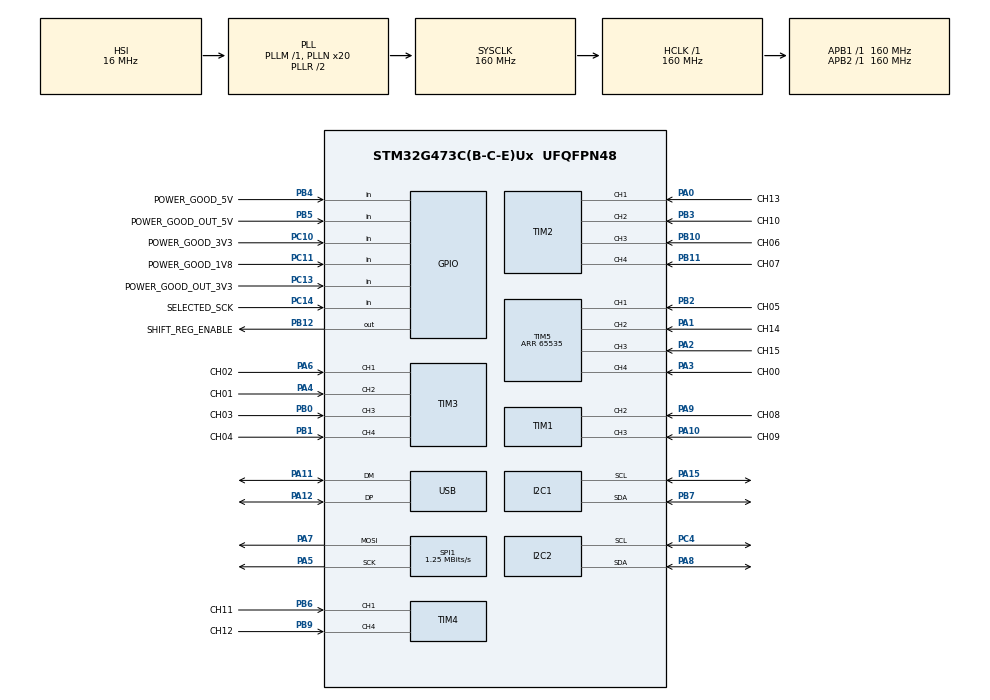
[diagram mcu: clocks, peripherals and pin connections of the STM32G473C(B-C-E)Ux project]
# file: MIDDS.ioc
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I2C1.Timing=0x30D29DE4
I2C2.Timing=0x30D29DE4
Mcu.Family=STM32G4
Mcu.Name=STM32G473C(B-C-E)Ux
Mcu.Package=UFQFPN48
NVIC.PriorityGroup=NVIC_PRIORITYGROUP_4
NVIC.TIM1_CC_IRQn=true\:0\:0\:false\:false\:true\:true\:true\:true
NVIC.TIM1_UP_TIM16_IRQn=true\:0\:0\:false\:false\:true\:true\:true\:true
NVIC.TIM2_IRQn=true\:0\:0\:false\:false\:true\:true\:true\:true
NVIC.TIM3_IRQn=true\:0\:0\:false\:false\:true\:true\:true\:true
NVIC.TIM4_IRQn=true\:0\:0\:false\:false\:true\:true\:true\:true
NVIC.TIM5_IRQn=true\:0\:0\:false\:false\:true\:true\:true\:true
NVIC.USB_LP_IRQn=true\:0\:0\:false\:false\:true\:false\:true\:true
PA0.GPIO_Label=CH13
PA0.GPIO_PuPd=GPIO_PULLDOWN
PA0.Signal=S_TIM2_CH1
PA1.GPIO_Label=CH14
PA1.GPIO_PuPd=GPIO_PULLDOWN
PA1.Signal=S_TIM5_CH2
PA10.GPIO_Label=CH09
PA10.GPIO_PuPd=GPIO_PULLDOWN
PA10.Signal=S_TIM1_CH3
PA11.Mode=Device
PA11.Signal=USB_DM
PA12.Mode=Device
PA12.Signal=USB_DP
PA13.Mode=Serial_Wire
PA13.Signal=SYS_JTMS-SWDIO
PA14.Mode=Serial_Wire
PA14.Signal=SYS_JTCK-SWCLK
PA15.Mode=I2C
PA15.Signal=I2C1_SCL
PA2.GPIO_Label=CH15
PA2.GPIO_PuPd=GPIO_PULLDOWN
PA2.Signal=S_TIM5_CH3
PA3.GPIO_Label=CH00
PA3.GPIO_PuPd=GPIO_PULLDOWN
PA3.Signal=S_TIM5_CH4
PA4.GPIO_Label=CH01
PA4.GPIO_PuPd=GPIO_PULLDOWN
PA4.Signal=S_TIM3_CH2
PA5.Mode=TX_Only_Simplex_Unidirect_Master
PA5.Signal=SPI1_SCK
PA6.GPIO_Label=CH02
PA6.GPIO_PuPd=GPIO_PULLDOWN
PA6.Signal=S_TIM3_CH1
PA7.Mode=TX_Only_Simplex_Unidirect_Master
PA7.Signal=SPI1_MOSI
PA8.Mode=I2C
PA8.Signal=I2C2_SDA
PA9.GPIO_Label=CH08
PA9.GPIO_PuPd=GPIO_PULLDOWN
PA9.Signal=S_TIM1_CH2
PB0.GPIO_Label=CH03
PB0.GPIO_PuPd=GPIO_PULLDOWN
PB0.Signal=S_TIM3_CH3
PB1.GPIO_Label=CH04
PB1.GPIO_PuPd=GPIO_PULLDOWN
PB1.Signal=S_TIM3_CH4
PB10.GPIO_Label=CH06
PB10.GPIO_PuPd=GPIO_PULLDOWN
PB10.Signal=S_TIM2_CH3
PB11.GPIO_Label=CH07
PB11.GPIO_PuPd=GPIO_PULLDOWN
PB11.Signal=S_TIM2_CH4
PB12.GPIO_Label=SHIFT_REG_ENABLE
PB12.Signal=GPIO_Output
PB2.GPIO_Label=CH05
PB2.GPIO_PuPd=GPIO_PULLDOWN
PB2.Signal=S_TIM5_CH1
PB3.GPIO_Label=CH10
PB3.GPIO_PuPd=GPIO_PULLDOWN
PB3.Signal=S_TIM2_CH2
PB4.GPIO_Label=POWER_GOOD_5V
PB4.Signal=GPIO_Input
PB5.GPIO_Label=POWER_GOOD_OUT_5V
PB5.Signal=GPIO_Input
PB6.GPIO_Label=CH11
PB6.GPIO_PuPd=GPIO_PULLDOWN
PB6.Signal=S_TIM4_CH1
PB7.Mode=I2C
PB7.Signal=I2C1_SDA
PB9.GPIO_Label=CH12
PB9.GPIO_PuPd=GPIO_PULLDOWN
PB9.Signal=S_TIM4_CH4
PC10.GPIO_Label=POWER_GOOD_3V3
PC10.Signal=GPIO_Input
PC11.GPIO_Label=POWER_GOOD_1V8
PC11.Signal=GPIO_Input
PC13.GPIO_Label=POWER_GOOD_OUT_3V3
PC13.Signal=GPIO_Input
PC14-OSC32_IN.GPIO_Label=SELECTED_SCK
PC14-OSC32_IN.Signal=GPIO_Input
PC4.Mode=I2C
PC4.Signal=I2C2_SCL
PF0-OSC_IN.Mode=HSE-External-Clock-Source
PF0-OSC_IN.Signal=RCC_OSC_IN
ProjectManager.HeapSize=0x200
ProjectManager.StackSize=0x400
ProjectManager.TargetToolchain=STM32CubeIDE
RCC.ADC12Freq_Value=160000000
RCC.ADC345Freq_Value=160000000
RCC.AHBFreq_Value=160000000
RCC.APB1Freq_Value=160000000
RCC.APB1TimFreq_Value=160000000
RCC.APB2Freq_Value=160000000
RCC.APB2TimFreq_Value=160000000
RCC.CK48CLockSelection=RCC_USBCLKSOURCE_HSI48
RCC.CortexFreq_Value=160000000
RCC.EXTERNAL_CLOCK_VALUE=12288000
RCC.HCLKFreq_Value=160000000
RCC.HSE_VALUE=10000000
RCC.HSI48_VALUE=48000000
RCC.HSI_VALUE=16000000
RCC.LSE_VALUE=32768
RCC.PLLN=20
RCC.PLLQ=RCC_PLLQ_DIV4
RCC.SYSCLKFreq_VALUE=160000000
RCC.SYSCLKSource=RCC_SYSCLKSOURCE_PLLCLK
RCC.USBFreq_Value=48000000
RCC.VCOOutputFreq_Value=320000000
SH.S_TIM1_CH2.0=TIM1_CH2,Input_Capture2_from_TI2
SH.S_TIM1_CH3.0=TIM1_CH3,Input_Capture3_from_TI3
SH.S_TIM2_CH1.0=TIM2_CH1,Input_Capture1_from_TI1
SH.S_TIM2_CH2.0=TIM2_CH2,Input_Capture2_from_TI2
SH.S_TIM2_CH3.0=TIM2_CH3,Input_Capture3_from_TI3
SH.S_TIM2_CH4.0=TIM2_CH4,Input_Capture4_from_TI4
SH.S_TIM3_CH1.0=TIM3_CH1,Input_Capture1_from_TI1
SH.S_TIM3_CH2.0=TIM3_CH2,Input_Capture2_from_TI2
SH.S_TIM3_CH3.0=TIM3_CH3,Input_Capture3_from_TI3
SH.S_TIM3_CH4.0=TIM3_CH4,Input_Capture4_from_TI4
SH.S_TIM4_CH1.0=TIM4_CH1,Input_Capture1_from_TI1
SH.S_TIM4_CH4.0=TIM4_CH4,Input_Capture4_from_TI4
SH.S_TIM5_CH1.0=TIM5_CH1,Input_Capture1_from_TI1
SH.S_TIM5_CH2.0=TIM5_CH2,Input_Capture2_from_TI2
SH.S_TIM5_CH3.0=TIM5_CH3,Input_Capture3_from_TI3
SH.S_TIM5_CH4.0=TIM5_CH4,Input_Capture4_from_TI4
SPI1.BaudRatePrescaler=SPI_BAUDRATEPRESCALER_128
SPI1.CalculateBaudRate=1.25 MBits/s
SPI1.DataSize=SPI_DATASIZE_8BIT
SPI1.Direction=SPI_DIRECTION_2LINES
SPI1.Mode=SPI_MODE_MASTER
SPI1.VirtualType=VM_MASTER
TIM1.Channel-Input_Capture1_from_TI1=TIM_CHANNEL_1
TIM1.Channel-Input_Capture2_from_TI2=TIM_CHANNEL_2
TIM1.Channel-Input_Capture3_from_TI3=TIM_CHANNEL_3
TIM1.ICPolarity_CH1=TIM_INPUTCHANNELPOLARITY_BOTHEDGE
TIM1.ICPolarity_CH2=TIM_INPUTCHANNELPOLARITY_BOTHEDGE
TIM1.ICPolarity_CH3=TIM_INPUTCHANNELPOLARITY_BOTHEDGE
TIM1.TIM_MasterOutputTrigger=TIM_TRGO_ENABLE
TIM1.TIM_MasterSlaveMode=TIM_MASTERSLAVEMODE_ENABLE
TIM2.Channel-Input_Capture1_from_TI1=TIM_CHANNEL_1
TIM2.Channel-Input_Capture2_from_TI2=TIM_CHANNEL_2
TIM2.Channel-Input_Capture3_from_TI3=TIM_CHANNEL_3
TIM2.Channel-Input_Capture4_from_TI4=TIM_CHANNEL_4
TIM2.ICPolarity_CH1=TIM_INPUTCHANNELPOLARITY_BOTHEDGE
TIM2.ICPolarity_CH2=TIM_INPUTCHANNELPOLARITY_BOTHEDGE
TIM2.ICPolarity_CH3=TIM_INPUTCHANNELPOLARITY_BOTHEDGE
TIM2.ICPolarity_CH4=TIM_INPUTCHANNELPOLARITY_BOTHEDGE
TIM3.Channel-Input_Capture1_from_TI1=TIM_CHANNEL_1
TIM3.Channel-Input_Capture2_from_TI2=TIM_CHANNEL_2
TIM3.Channel-Input_Capture3_from_TI3=TIM_CHANNEL_3
TIM3.Channel-Input_Capture4_from_TI4=TIM_CHANNEL_4
TIM3.ICPolarity_CH1=TIM_INPUTCHANNELPOLARITY_BOTHEDGE
TIM3.ICPolarity_CH2=TIM_INPUTCHANNELPOLARITY_BOTHEDGE
TIM3.ICPolarity_CH3=TIM_INPUTCHANNELPOLARITY_BOTHEDGE
TIM3.ICPolarity_CH4=TIM_INPUTCHANNELPOLARITY_BOTHEDGE
TIM4.Channel-Input_Capture1_from_TI1=TIM_CHANNEL_1
TIM4.Channel-Input_Capture4_from_TI4=TIM_CHANNEL_4
TIM4.ICPolarity_CH1=TIM_INPUTCHANNELPOLARITY_BOTHEDGE
TIM4.ICPolarity_CH4=TIM_INPUTCHANNELPOLARITY_BOTHEDGE
TIM5.Channel-Input_Capture1_from_TI1=TIM_CHANNEL_1
TIM5.Channel-Input_Capture2_from_TI2=TIM_CHANNEL_2
TIM5.Channel-Input_Capture3_from_TI3=TIM_CHANNEL_3
TIM5.Channel-Input_Capture4_from_TI4=TIM_CHANNEL_4
TIM5.PeriodNoDither=65535
USB_DEVICE.CLASS_NAME_FS=CDC
USB_DEVICE.VirtualMode=Cdc
USB_DEVICE.VirtualModeFS=Cdc_FS
VP_SYS_VS_DBSignals.Mode=DisableDeadBatterySignals
VP_TIM1_VS_ClockSourceINT.Mode=Internal
VP_TIM2_VS_ClockSourceINT.Mode=Internal
VP_TIM2_VS_ClockSourceITR.Mode=TriggerSource_ITR0
VP_TIM2_VS_ControllerModeReset.Mode=Reset Mode
VP_TIM3_VS_ClockSourceINT.Mode=Internal
VP_TIM3_VS_ClockSourceITR.Mode=TriggerSource_ITR0
VP_TIM3_VS_ControllerModeReset.Mode=Reset Mode
VP_TIM4_VS_ClockSourceINT.Mode=Internal
VP_TIM4_VS_ClockSourceITR.Mode=TriggerSource_ITR0
VP_TIM4_VS_ControllerModeReset.Mode=Reset Mode
VP_TIM5_VS_ClockSourceINT.Mode=Internal
VP_TIM5_VS_ClockSourceITR.Mode=TriggerSource_ITR0
VP_TIM5_VS_ControllerModeReset.Mode=Reset Mode
VP_USB_DEVICE_VS_USB_DEVICE_CDC_FS.Mode=CDC_FS
board=custom

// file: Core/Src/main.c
/* USER CODE BEGIN Header */
/**
  ******************************************************************************
  * @file           : main.c
  * @brief          : Main program body
  ******************************************************************************
  * @attention
  *
  * Copyright (c) 2025 STMicroelectronics.
  * All rights reserved.
  *
  * This software is licensed under terms that can be found in the LICENSE file
  * in the root directory of this software component.
  * If no LICENSE file comes with this software, it is provided AS-IS.
  *
  ******************************************************************************
  */
/* USER CODE END Header */
#include "main.h"
#include "usb_device.h"

/* USER CODE BEGIN Includes */
#include "MainMCU.h"
/* USER CODE END Includes */

I2C_HandleTypeDef hi2c1;
I2C_HandleTypeDef hi2c2;

SPI_HandleTypeDef hspi1;

TIM_HandleTypeDef htim1;
TIM_HandleTypeDef htim2;
TIM_HandleTypeDef htim3;
TIM_HandleTypeDef htim4;
TIM_HandleTypeDef htim5;

void SystemClock_Config(void);
static void MX_GPIO_Init(void);
static void MX_TIM1_Init(void);
static void MX_TIM2_Init(void);
static void MX_TIM3_Init(void);
static void MX_TIM4_Init(void);
static void MX_I2C1_Init(void);
static void MX_I2C2_Init(void);
static void MX_SPI1_Init(void);
static void MX_TIM5_Init(void);

int main(void)
{

  /* MCU Configuration--------------------------------------------------------*/

  /* Reset of all peripherals, Initializes the Flash interface and the Systick. */
  HAL_Init();

  /* Configure the system clock */
  SystemClock_Config();

  /* Initialize all configured peripherals */
  MX_GPIO_Init();
  MX_TIM1_Init();
  MX_TIM2_Init();
  MX_TIM3_Init();
  MX_TIM4_Init();
  MX_USB_Device_Init();
  MX_I2C1_Init();
  MX_I2C2_Init();
  MX_SPI1_Init();
  MX_TIM5_Init();
  /* USER CODE BEGIN 2 */
  initMCU(&htim1, &htim2, &htim3, &htim4, &htim5, &hspi1, &hi2c1, &hi2c2);
  /* USER CODE END 2 */

  /* Infinite loop */
  while (1)
  {

    /* USER CODE BEGIN 3 */
    loopMCU();
  }
  /* USER CODE END 3 */
}

void SystemClock_Config(void)
{
  RCC_OscInitTypeDef RCC_OscInitStruct = {0};
  RCC_ClkInitTypeDef RCC_ClkInitStruct = {0};

  /** Configure the main internal regulator output voltage
  */
  HAL_PWREx_ControlVoltageScaling(PWR_REGULATOR_VOLTAGE_SCALE1_BOOST);

  /** Initializes the RCC Oscillators according to the specified parameters
  * in the RCC_OscInitTypeDef structure.
  */
  RCC_OscInitStruct.OscillatorType = RCC_OSCILLATORTYPE_HSI|RCC_OSCILLATORTYPE_HSI48;
  RCC_OscInitStruct.HSIState = RCC_HSI_ON;
  RCC_OscInitStruct.HSICalibrationValue = RCC_HSICALIBRATION_DEFAULT;
  RCC_OscInitStruct.HSI48State = RCC_HSI48_ON;
  RCC_OscInitStruct.PLL.PLLState = RCC_PLL_ON;
  RCC_OscInitStruct.PLL.PLLSource = RCC_PLLSOURCE_HSI;
  RCC_OscInitStruct.PLL.PLLM = RCC_PLLM_DIV1;
  RCC_OscInitStruct.PLL.PLLN = 20;
  RCC_OscInitStruct.PLL.PLLP = RCC_PLLP_DIV2;
  RCC_OscInitStruct.PLL.PLLQ = RCC_PLLQ_DIV4;
  RCC_OscInitStruct.PLL.PLLR = RCC_PLLR_DIV2;
  if (HAL_RCC_OscConfig(&RCC_OscInitStruct) != HAL_OK)
  {
    Error_Handler();
  }

  /** Initializes the CPU, AHB and APB buses clocks
  */
  RCC_ClkInitStruct.ClockType = RCC_CLOCKTYPE_HCLK|RCC_CLOCKTYPE_SYSCLK
                              |RCC_CLOCKTYPE_PCLK1|RCC_CLOCKTYPE_PCLK2;
  RCC_ClkInitStruct.SYSCLKSource = RCC_SYSCLKSOURCE_PLLCLK;
  RCC_ClkInitStruct.AHBCLKDivider = RCC_SYSCLK_DIV1;
  RCC_ClkInitStruct.APB1CLKDivider = RCC_HCLK_DIV1;
  RCC_ClkInitStruct.APB2CLKDivider = RCC_HCLK_DIV1;

  if (HAL_RCC_ClockConfig(&RCC_ClkInitStruct, FLASH_LATENCY_4) != HAL_OK)
  {
    Error_Handler();
  }
}

static void MX_I2C1_Init(void)
{

  hi2c1.Instance = I2C1;
  hi2c1.Init.Timing = 0x30D29DE4;
  hi2c1.Init.OwnAddress1 = 0;
  hi2c1.Init.AddressingMode = I2C_ADDRESSINGMODE_7BIT;
  hi2c1.Init.DualAddressMode = I2C_DUALADDRESS_DISABLE;
  hi2c1.Init.OwnAddress2 = 0;
  hi2c1.Init.OwnAddress2Masks = I2C_OA2_NOMASK;
  hi2c1.Init.GeneralCallMode = I2C_GENERALCALL_DISABLE;
  hi2c1.Init.NoStretchMode = I2C_NOSTRETCH_DISABLE;
  if (HAL_I2C_Init(&hi2c1) != HAL_OK)
  {
    Error_Handler();
  }

  /** Configure Analogue filter
  */
  if (HAL_I2CEx_ConfigAnalogFilter(&hi2c1, I2C_ANALOGFILTER_ENABLE) != HAL_OK)
  {
    Error_Handler();
  }

  /** Configure Digital filter
  */
  if (HAL_I2CEx_ConfigDigitalFilter(&hi2c1, 0) != HAL_OK)
  {
    Error_Handler();
  }

}

static void MX_I2C2_Init(void)
{

  hi2c2.Instance = I2C2;
  hi2c2.Init.Timing = 0x30D29DE4;
  hi2c2.Init.OwnAddress1 = 0;
  hi2c2.Init.AddressingMode = I2C_ADDRESSINGMODE_7BIT;
  hi2c2.Init.DualAddressMode = I2C_DUALADDRESS_DISABLE;
  hi2c2.Init.OwnAddress2 = 0;
  hi2c2.Init.OwnAddress2Masks = I2C_OA2_NOMASK;
  hi2c2.Init.GeneralCallMode = I2C_GENERALCALL_DISABLE;
  hi2c2.Init.NoStretchMode = I2C_NOSTRETCH_DISABLE;
  if (HAL_I2C_Init(&hi2c2) != HAL_OK)
  {
    Error_Handler();
  }

  /** Configure Analogue filter
  */
  if (HAL_I2CEx_ConfigAnalogFilter(&hi2c2, I2C_ANALOGFILTER_ENABLE) != HAL_OK)
  {
    Error_Handler();
  }

  /** Configure Digital filter
  */
  if (HAL_I2CEx_ConfigDigitalFilter(&hi2c2, 0) != HAL_OK)
  {
    Error_Handler();
  }

}

static void MX_SPI1_Init(void)
{

  /* SPI1 parameter configuration*/
  hspi1.Instance = SPI1;
  hspi1.Init.Mode = SPI_MODE_MASTER;
  hspi1.Init.Direction = SPI_DIRECTION_2LINES;
  hspi1.Init.DataSize = SPI_DATASIZE_8BIT;
  hspi1.Init.CLKPolarity = SPI_POLARITY_LOW;
  hspi1.Init.CLKPhase = SPI_PHASE_1EDGE;
  hspi1.Init.NSS = SPI_NSS_SOFT;
  hspi1.Init.BaudRatePrescaler = SPI_BAUDRATEPRESCALER_128;
  hspi1.Init.FirstBit = SPI_FIRSTBIT_MSB;
  hspi1.Init.TIMode = SPI_TIMODE_DISABLE;
  hspi1.Init.CRCCalculation = SPI_CRCCALCULATION_DISABLE;
  hspi1.Init.CRCPolynomial = 7;
  hspi1.Init.CRCLength = SPI_CRC_LENGTH_DATASIZE;
  hspi1.Init.NSSPMode = SPI_NSS_PULSE_ENABLE;
  if (HAL_SPI_Init(&hspi1) != HAL_OK)
  {
    Error_Handler();
  }

}

static void MX_TIM1_Init(void)
{

  TIM_ClockConfigTypeDef sClockSourceConfig = {0};
  TIM_MasterConfigTypeDef sMasterConfig = {0};
  TIM_IC_InitTypeDef sConfigIC = {0};

  htim1.Instance = TIM1;
  htim1.Init.Prescaler = 0;
  htim1.Init.CounterMode = TIM_COUNTERMODE_UP;
  htim1.Init.Period = 65535;
  htim1.Init.ClockDivision = TIM_CLOCKDIVISION_DIV1;
  htim1.Init.RepetitionCounter = 0;
  htim1.Init.AutoReloadPreload = TIM_AUTORELOAD_PRELOAD_DISABLE;
  if (HAL_TIM_Base_Init(&htim1) != HAL_OK)
  {
    Error_Handler();
  }
  sClockSourceConfig.ClockSource = TIM_CLOCKSOURCE_INTERNAL;
  if (HAL_TIM_ConfigClockSource(&htim1, &sClockSourceConfig) != HAL_OK)
  {
    Error_Handler();
  }
  if (HAL_TIM_IC_Init(&htim1) != HAL_OK)
  {
    Error_Handler();
  }
  sMasterConfig.MasterOutputTrigger = TIM_TRGO_ENABLE;
  sMasterConfig.MasterOutputTrigger2 = TIM_TRGO2_RESET;
  sMasterConfig.MasterSlaveMode = TIM_MASTERSLAVEMODE_ENABLE;
  if (HAL_TIMEx_MasterConfigSynchronization(&htim1, &sMasterConfig) != HAL_OK)
  {
    Error_Handler();
  }
  sConfigIC.ICPolarity = TIM_INPUTCHANNELPOLARITY_BOTHEDGE;
  sConfigIC.ICSelection = TIM_ICSELECTION_DIRECTTI;
  sConfigIC.ICPrescaler = TIM_ICPSC_DIV1;
  sConfigIC.ICFilter = 0;
  if (HAL_TIM_IC_ConfigChannel(&htim1, &sConfigIC, TIM_CHANNEL_2) != HAL_OK)
  {
    Error_Handler();
  }
  if (HAL_TIM_IC_ConfigChannel(&htim1, &sConfigIC, TIM_CHANNEL_3) != HAL_OK)
  {
    Error_Handler();
  }

}

static void MX_TIM2_Init(void)
{

  TIM_ClockConfigTypeDef sClockSourceConfig = {0};
  TIM_SlaveConfigTypeDef sSlaveConfig = {0};
  TIM_MasterConfigTypeDef sMasterConfig = {0};
  TIM_IC_InitTypeDef sConfigIC = {0};

  htim2.Instance = TIM2;
  htim2.Init.Prescaler = 0;
  htim2.Init.CounterMode = TIM_COUNTERMODE_UP;
  htim2.Init.Period = 4294967295;
  htim2.Init.ClockDivision = TIM_CLOCKDIVISION_DIV1;
  htim2.Init.AutoReloadPreload = TIM_AUTORELOAD_PRELOAD_DISABLE;
  if (HAL_TIM_Base_Init(&htim2) != HAL_OK)
  {
    Error_Handler();
  }
  sClockSourceConfig.ClockSource = TIM_CLOCKSOURCE_INTERNAL;
  if (HAL_TIM_ConfigClockSource(&htim2, &sClockSourceConfig) != HAL_OK)
  {
    Error_Handler();
  }
  if (HAL_TIM_IC_Init(&htim2) != HAL_OK)
  {
    Error_Handler();
  }
  sSlaveConfig.SlaveMode = TIM_SLAVEMODE_RESET;
  sSlaveConfig.InputTrigger = TIM_TS_ITR0;
  if (HAL_TIM_SlaveConfigSynchro(&htim2, &sSlaveConfig) != HAL_OK)
  {
    Error_Handler();
  }
  sMasterConfig.MasterOutputTrigger = TIM_TRGO_RESET;
  sMasterConfig.MasterSlaveMode = TIM_MASTERSLAVEMODE_DISABLE;
  if (HAL_TIMEx_MasterConfigSynchronization(&htim2, &sMasterConfig) != HAL_OK)
  {
    Error_Handler();
  }
  sConfigIC.ICPolarity = TIM_INPUTCHANNELPOLARITY_BOTHEDGE;
  sConfigIC.ICSelection = TIM_ICSELECTION_DIRECTTI;
  sConfigIC.ICPrescaler = TIM_ICPSC_DIV1;
  sConfigIC.ICFilter = 0;
  if (HAL_TIM_IC_ConfigChannel(&htim2, &sConfigIC, TIM_CHANNEL_1) != HAL_OK)
  {
    Error_Handler();
  }
  if (HAL_TIM_IC_ConfigChannel(&htim2, &sConfigIC, TIM_CHANNEL_2) != HAL_OK)
  {
    Error_Handler();
  }
  if (HAL_TIM_IC_ConfigChannel(&htim2, &sConfigIC, TIM_CHANNEL_3) != HAL_OK)
  {
    Error_Handler();
  }
  if (HAL_TIM_IC_ConfigChannel(&htim2, &sConfigIC, TIM_CHANNEL_4) != HAL_OK)
  {
    Error_Handler();
  }

}

static void MX_TIM3_Init(void)
{

  TIM_ClockConfigTypeDef sClockSourceConfig = {0};
  TIM_SlaveConfigTypeDef sSlaveConfig = {0};
  TIM_MasterConfigTypeDef sMasterConfig = {0};
  TIM_IC_InitTypeDef sConfigIC = {0};

  htim3.Instance = TIM3;
  htim3.Init.Prescaler = 0;
  htim3.Init.CounterMode = TIM_COUNTERMODE_UP;
  htim3.Init.Period = 65535;
  htim3.Init.ClockDivision = TIM_CLOCKDIVISION_DIV1;
  htim3.Init.AutoReloadPreload = TIM_AUTORELOAD_PRELOAD_DISABLE;
  if (HAL_TIM_Base_Init(&htim3) != HAL_OK)
  {
    Error_Handler();
  }
  sClockSourceConfig.ClockSource = TIM_CLOCKSOURCE_INTERNAL;
  if (HAL_TIM_ConfigClockSource(&htim3, &sClockSourceConfig) != HAL_OK)
  {
    Error_Handler();
  }
  if (HAL_TIM_IC_Init(&htim3) != HAL_OK)
  {
    Error_Handler();
  }
  sSlaveConfig.SlaveMode = TIM_SLAVEMODE_RESET;
  sSlaveConfig.InputTrigger = TIM_TS_ITR0;
  if (HAL_TIM_SlaveConfigSynchro(&htim3, &sSlaveConfig) != HAL_OK)
  {
    Error_Handler();
  }
  sMasterConfig.MasterOutputTrigger = TIM_TRGO_RESET;
  sMasterConfig.MasterSlaveMode = TIM_MASTERSLAVEMODE_DISABLE;
  if (HAL_TIMEx_MasterConfigSynchronization(&htim3, &sMasterConfig) != HAL_OK)
  {
    Error_Handler();
  }
  sConfigIC.ICPolarity = TIM_INPUTCHANNELPOLARITY_BOTHEDGE;
  sConfigIC.ICSelection = TIM_ICSELECTION_DIRECTTI;
  sConfigIC.ICPrescaler = TIM_ICPSC_DIV1;
  sConfigIC.ICFilter = 0;
  if (HAL_TIM_IC_ConfigChannel(&htim3, &sConfigIC, TIM_CHANNEL_1) != HAL_OK)
  {
    Error_Handler();
  }
  if (HAL_TIM_IC_ConfigChannel(&htim3, &sConfigIC, TIM_CHANNEL_2) != HAL_OK)
  {
    Error_Handler();
  }
  if (HAL_TIM_IC_ConfigChannel(&htim3, &sConfigIC, TIM_CHANNEL_3) != HAL_OK)
  {
    Error_Handler();
  }
  if (HAL_TIM_IC_ConfigChannel(&htim3, &sConfigIC, TIM_CHANNEL_4) != HAL_OK)
  {
    Error_Handler();
  }

}

static void MX_TIM4_Init(void)
{

  TIM_ClockConfigTypeDef sClockSourceConfig = {0};
  TIM_SlaveConfigTypeDef sSlaveConfig = {0};
  TIM_MasterConfigTypeDef sMasterConfig = {0};
  TIM_IC_InitTypeDef sConfigIC = {0};

  htim4.Instance = TIM4;
  htim4.Init.Prescaler = 0;
  htim4.Init.CounterMode = TIM_COUNTERMODE_UP;
  htim4.Init.Period = 65535;
  htim4.Init.ClockDivision = TIM_CLOCKDIVISION_DIV1;
  htim4.Init.AutoReloadPreload = TIM_AUTORELOAD_PRELOAD_DISABLE;
  if (HAL_TIM_Base_Init(&htim4) != HAL_OK)
  {
    Error_Handler();
  }
  sClockSourceConfig.ClockSource = TIM_CLOCKSOURCE_INTERNAL;
  if (HAL_TIM_ConfigClockSource(&htim4, &sClockSourceConfig) != HAL_OK)
  {
    Error_Handler();
  }
  if (HAL_TIM_IC_Init(&htim4) != HAL_OK)
  {
    Error_Handler();
  }
  sSlaveConfig.SlaveMode = TIM_SLAVEMODE_RESET;
  sSlaveConfig.InputTrigger = TIM_TS_ITR0;
  if (HAL_TIM_SlaveConfigSynchro(&htim4, &sSlaveConfig) != HAL_OK)
  {
    Error_Handler();
  }
  sMasterConfig.MasterOutputTrigger = TIM_TRGO_RESET;
  sMasterConfig.MasterSlaveMode = TIM_MASTERSLAVEMODE_DISABLE;
  if (HAL_TIMEx_MasterConfigSynchronization(&htim4, &sMasterConfig) != HAL_OK)
  {
    Error_Handler();
  }
  sConfigIC.ICPolarity = TIM_INPUTCHANNELPOLARITY_BOTHEDGE;
  sConfigIC.ICSelection = TIM_ICSELECTION_DIRECTTI;
  sConfigIC.ICPrescaler = TIM_ICPSC_DIV1;
  sConfigIC.ICFilter = 0;
  if (HAL_TIM_IC_ConfigChannel(&htim4, &sConfigIC, TIM_CHANNEL_1) != HAL_OK)
  {
    Error_Handler();
  }
  if (HAL_TIM_IC_ConfigChannel(&htim4, &sConfigIC, TIM_CHANNEL_4) != HAL_OK)
  {
    Error_Handler();
  }

}

static void MX_TIM5_Init(void)
{

  TIM_ClockConfigTypeDef sClockSourceConfig = {0};
  TIM_SlaveConfigTypeDef sSlaveConfig = {0};
  TIM_MasterConfigTypeDef sMasterConfig = {0};
  TIM_IC_InitTypeDef sConfigIC = {0};

  htim5.Instance = TIM5;
  htim5.Init.Prescaler = 0;
  htim5.Init.CounterMode = TIM_COUNTERMODE_UP;
  htim5.Init.Period = 65535;
  htim5.Init.ClockDivision = TIM_CLOCKDIVISION_DIV1;
  htim5.Init.AutoReloadPreload = TIM_AUTORELOAD_PRELOAD_DISABLE;
  if (HAL_TIM_Base_Init(&htim5) != HAL_OK)
  {
    Error_Handler();
  }
  sClockSourceConfig.ClockSource = TIM_CLOCKSOURCE_INTERNAL;
  if (HAL_TIM_ConfigClockSource(&htim5, &sClockSourceConfig) != HAL_OK)
  {
    Error_Handler();
  }
  if (HAL_TIM_IC_Init(&htim5) != HAL_OK)
  {
    Error_Handler();
  }
  sSlaveConfig.SlaveMode = TIM_SLAVEMODE_RESET;
  sSlaveConfig.InputTrigger = TIM_TS_ITR0;
  if (HAL_TIM_SlaveConfigSynchro(&htim5, &sSlaveConfig) != HAL_OK)
  {
    Error_Handler();
  }
  sMasterConfig.MasterOutputTrigger = TIM_TRGO_RESET;
  sMasterConfig.MasterSlaveMode = TIM_MASTERSLAVEMODE_DISABLE;
  if (HAL_TIMEx_MasterConfigSynchronization(&htim5, &sMasterConfig) != HAL_OK)
  {
    Error_Handler();
  }
  sConfigIC.ICPolarity = TIM_INPUTCHANNELPOLARITY_RISING;
  sConfigIC.ICSelection = TIM_ICSELECTION_DIRECTTI;
  sConfigIC.ICPrescaler = TIM_ICPSC_DIV1;
  sConfigIC.ICFilter = 0;
  if (HAL_TIM_IC_ConfigChannel(&htim5, &sConfigIC, TIM_CHANNEL_1) != HAL_OK)
  {
    Error_Handler();
  }
  if (HAL_TIM_IC_ConfigChannel(&htim5, &sConfigIC, TIM_CHANNEL_2) != HAL_OK)
  {
    Error_Handler();
  }
  if (HAL_TIM_IC_ConfigChannel(&htim5, &sConfigIC, TIM_CHANNEL_3) != HAL_OK)
  {
    Error_Handler();
  }
  if (HAL_TIM_IC_ConfigChannel(&htim5, &sConfigIC, TIM_CHANNEL_4) != HAL_OK)
  {
    Error_Handler();
  }

}

static void MX_GPIO_Init(void)
{
  GPIO_InitTypeDef GPIO_InitStruct = {0};

  /* GPIO Ports Clock Enable */
  __HAL_RCC_GPIOC_CLK_ENABLE();
  __HAL_RCC_GPIOF_CLK_ENABLE();
  __HAL_RCC_GPIOA_CLK_ENABLE();
  __HAL_RCC_GPIOB_CLK_ENABLE();

  /*Configure GPIO pin Output Level */
  HAL_GPIO_WritePin(SHIFT_REG_ENABLE_GPIO_Port, SHIFT_REG_ENABLE_Pin, GPIO_PIN_RESET);

  /*Configure GPIO pins : POWER_GOOD_OUT_3V3_Pin SELECTED_SCK_Pin POWER_GOOD_3V3_Pin POWER_GOOD_1V8_Pin */
  GPIO_InitStruct.Pin = POWER_GOOD_OUT_3V3_Pin|SELECTED_SCK_Pin|POWER_GOOD_3V3_Pin|POWER_GOOD_1V8_Pin;
  GPIO_InitStruct.Mode = GPIO_MODE_INPUT;
  GPIO_InitStruct.Pull = GPIO_NOPULL;
  HAL_GPIO_Init(GPIOC, &GPIO_InitStruct);

  /*Configure GPIO pin : SHIFT_REG_ENABLE_Pin */
  GPIO_InitStruct.Pin = SHIFT_REG_ENABLE_Pin;
  GPIO_InitStruct.Mode = GPIO_MODE_OUTPUT_PP;
  GPIO_InitStruct.Pull = GPIO_NOPULL;
  GPIO_InitStruct.Speed = GPIO_SPEED_FREQ_LOW;
  HAL_GPIO_Init(SHIFT_REG_ENABLE_GPIO_Port, &GPIO_InitStruct);

  /*Configure GPIO pins : POWER_GOOD_5V_Pin POWER_GOOD_OUT_5V_Pin */
  GPIO_InitStruct.Pin = POWER_GOOD_5V_Pin|POWER_GOOD_OUT_5V_Pin;
  GPIO_InitStruct.Mode = GPIO_MODE_INPUT;
  GPIO_InitStruct.Pull = GPIO_NOPULL;
  HAL_GPIO_Init(GPIOB, &GPIO_InitStruct);

}

void Error_Handler(void)
{
  __disable_irq();
  while (1)
  {
  }
}
